# RL6845_IP_SVD register map
Vendor: Realtek
Registers are 32-bit, read-write, reset 0x0 unless marked. A register's access mark holds for its fields unless they carry their own. Offsets are from the block's base; [hi:lo] are bit positions; {n}, {i} and the like mark numbered series.

## ipsec
Base 0x40100000
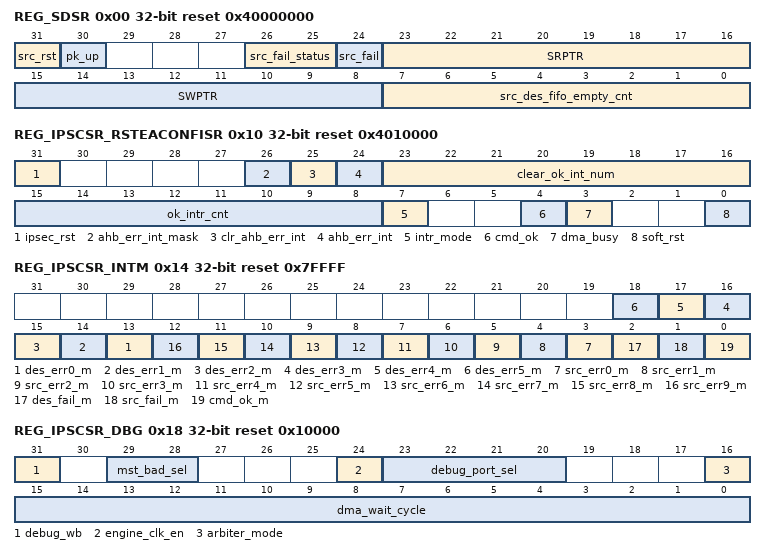
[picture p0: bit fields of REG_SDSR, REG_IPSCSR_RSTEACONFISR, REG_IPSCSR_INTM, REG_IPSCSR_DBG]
0x00 REG_SDSR access per field reset 0x40000000 — Source Descriptor Status Register
  [31] src_rst rw — Source descriptor reset. (only for pk_up = 1'b1)
  [30] pk_up rw — Packet base update wptr to engine. If pk_up =1, the total number of source descriptor in one packet can't be over 16, and the total number of destination descriptor in one packet can't be over 8.
  [26:25] src_fail_status ro — Source descriptor failed status. 2'd1: Users write the first word twice consecutively 2'd2: Users write the second word directly without writing first word in the beginning 2'd3: Overflow (Detect users try to write source descriptor, but there isn't available FIFO node to use).
  [24] src_fail rw — Source descriptor failed interrupt. Write 1 to clear this bit.
  [23:16] SRPTR ro — Source descriptor FIFO read pointer. When engine reads a descriptor and finishes it, SRPTR = SRPTR+2.
  [15:8] SWPTR ro — Source descriptor FIFO write pointer. When write descriptor to SDSW successfully, SWPTR = SWPTR+2.
  [7:0] src_des_fifo_empty_cnt ro — Source descriptor FIFO empty counter. Use this field to check how many available FIFO nodes in source descriptor FIFO could use.
0x04 REG_SDFWR — Source Descriptor First Word Register
  [31:0] SDFW — Source Descriptor First Word
0x08 REG_SDSWR — Source Descriptor Second Word Register
  [31:0] SDSW — Source Descriptor Second Word
0x10 REG_IPSCSR_RSTEACONFISR access per field reset 0x4010000 — Reset Engine and Configure Interrupt Service Routine Register
  [31] ipsec_rst rw — IPsec engine reset. Write '1' to reset the crypto engine and DMA engine (used to clear fatal error).
  [26] ahb_err_int_mask rw
  [25] clr_ahb_err_int rw
  [24] ahb_err_int ro
  [23:16] clear_ok_int_num rw — Clear ok interrupt number. In interrupt counter mode, if the programmer wants to clear ok_intr_cnt, need to write ok_intr_cnt to this field first, then write '1' to cmd_ok.
  [15:8] ok_intr_cnt ro — Ok interrupt counter. Reading this field can know how many interrupts are coming to notify that crypto engine has calculated cryptographic feature results. Use this field in interrupt counter mode.
  [7] intr_mode rw — Select ok interrupt mode: 1'd0: Interrupt mode is general mode. 1'd1: Interrupt mode is counter mode. · General mode means no matter how many interrupts are coming to notify that crypto engine has calculated cryptographic feature results. There is always one interrupt signal shows in cmd_ok field, and nothing in ok_intr_cnt. So if the programmer want to clear this signal, just write '1' to cmd_ok. · Counter mode means the programmer can know how many interrupts are coming to notify that crypto engine has calculated cryptographic feature results from ok_intr_cnt. The programmer also can know there are at least one interrupt from reading cmd_ok. So if the programmer want to clear ok_intr_cnt signals, need to write ok_intr_cnt into clear_ok_int_num, then write '1' to cmd_ok.
  [4] cmd_ok rw — Command ok Interrupt. Reading this field to detect whether crypto engine has calculated a cryptographic feature result. Even if interrupt mode is counter mode, still can use this field to detect whether an interrupt is coming. Write '1' to clear this interrupt signal.
  [3] dma_busy ro — Detect whether IPsec DMA is busy: 1'd0: DMA is not busy 1'd1: DMA is busy Used for debug to avoid data coherence issue (when user gets crypto finish calculated interrupt, user can make sure DMA engine has already move data to result buffer.)
  [0] soft_rst wo — Software reset. Write '1' to reset the crypto engine.
0x14 REG_IPSCSR_INTM reset 0x7FFFF — Interrupt Mask Register
  [n+13] des_err{n}_m (n=0..5) — Destination Descriptor Error {n} Interrupt Mask 1'd0: Disable mask 1'd1: Enable mask
  [n+3] src_err{n}_m (n=0..9) — Source Descriptor Error {n} Interrupt Mask 1'd0: Disable mask 1'd1: Enable mask
  [2] des_fail_m — Source Descriptor fail interrupt mask. 1'd0: Disable mask 1'd1: Enable mask
  [1] src_fail_m — Destination Descriptor fail interrupt mask. 1'd0: Disable mask 1'd1: Enable mask
  [0] cmd_ok_m — Command ok Interrupt Mask. 1'd0: Disable mask 1'd1: Enable mask If the programmer wants to disable cmd_ok interrupt signal, write '1' to enable interrupt mask.
0x18 REG_IPSCSR_DBG reset 0x10000 — Debug Register
  [31] debug_wb — Debug: write back mode. 1'd0: Disable DMA write back mode. 1'd1: Enable DMA write back mode. Enable this field, crypto DMA will move data from source address to destination address. During this period, the data won't be processed in any calculation (encryption, decryption, hash), then the programmer can check whether the source data is the same as destination data.
  [29:28] mst_bad_sel — (For debug port) select Lexra master data bus (option) 2'd0: mst_ipsec_bad[07:00] 2'd1: mst_ipsec_bad[15:08] 2'd2: mst_ipsec_bad[23:16] 2'd3: mst_ipsec_bad[31:24]
  [24] engine_clk_en — IPsec engine clock enable 1'd0: Disable IPsec engine clock 1'd1: Enable IPsec engine clock
  [23:20] debug_port_sel — Debug port selection 4'd0: engine_debug 4'd1: dma_lexra_debug 4'd2: dma_rx_debug 4'd3: dma_tx_debug
  [16] arbiter_mode — DMA arbiter mode: 1'd0: round-robin 1'd1: detect fifo wasted level There are 2 FIFOs in DMA, that are read-FIFO and write-FIFO. Detecting FIFO wasted level means that DMA will process which FIFO first depends on which wasted level is high. Because the wasted level is high means there are many FIFO nodes waiting to be processed in this FIFO, so DMA must process them in hurry.
  [15:0] dma_wait_cycle — Setting DMA wait cycles to assert next DMA request
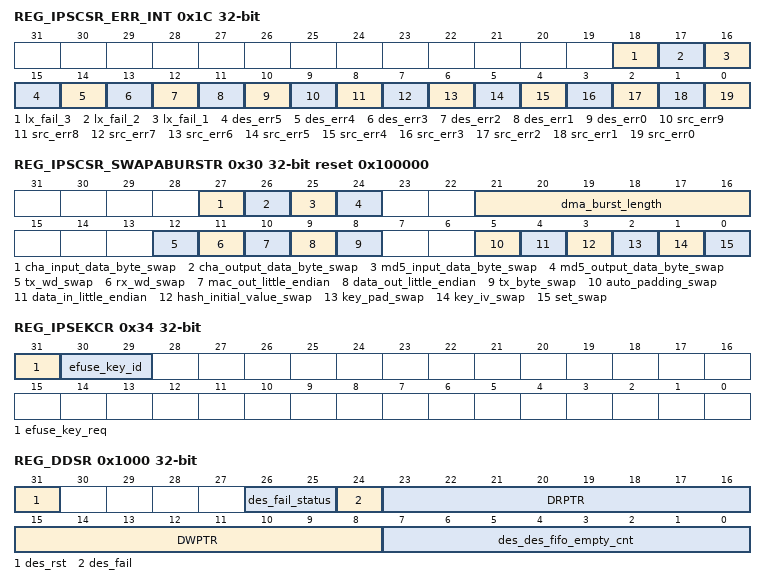
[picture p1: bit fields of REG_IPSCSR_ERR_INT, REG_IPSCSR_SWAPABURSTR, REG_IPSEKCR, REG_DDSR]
0x1C REG_IPSCSR_ERR_INT ro — Error Interrupt Register
  [18] lx_fail_3 — When a burst done, burst length != burst cnt. Write "1" to clear this error signal.
  [17] lx_fail_2 — When IPsec is working, rdata from bus != rdata of ipsec or wdata of ipsec != wdata on bus Write "1" to clear this error signal.
  [16] lx_fail_1 — LX bus timing issue Write "1" to clear this error signal.
  [15] des_err5 — Destination Descriptor Error 5 Interrupt. The error condition is authentication digest length error in destination descriptor. MD5: adl != 16 or SHA1: adl != 20 or SHA2-224: adl != 28 or adl != 32 when set sequential hash and not sequential hash last SHA2-256: adl != 32 or SHA2-384: adl != 48 or adl != 64 when set sequential hash and not sequential hash last SHA2-512: adl != 64 Write '1' to clear this error signal.
  [14] des_err4 — Destination Descriptor Error 4 Interrupt. The error condition is authentication digest length error in destination descriptor. MD5: adl > 16 or SHA1: adl > 20 or SHA2-224: adl > 28 or adl > 32when set sequential hash and not sequential hash last SHA2-256: adl > 32 or SHA2-384: adl > 48 or adl > 64when set sequential hash and not sequential hash last SHA2-512: adl > 64 Write '1' to clear this error signal.
  [13] des_err3 — Destination Descriptor Error 3 Interrupt. One of the error condition is that the sum of enl is greater than Encryption Total Length. The other error condition is about destination descriptor length error ((enl(Encryption length)==0) & (adl(authentication data length)==0)). Write '1' to clear this error signal. Sum of enl reference the register REG_IPSCSR_SENLR (offset 0x24).
  [12] des_err2 — Destination Descriptor Error 2 Interrupt. The error condition is the bit field ENC=1'b0 (active Hash engine to process hash data), but only active cipher engine. Write '1' to clear this error signal.
  [11] des_err1 — Destination Descriptor Error 1 Interrupt. The error condition is the bit field ENC=1'b1 (active cipher engine to process cipher data), but only active hash engine. Write '1' to clear this error signal.
  [10] des_err0 — Destination Descriptor Error 0 Interrupt. One of the error condition is destination descriptor starting address error (DDSA[1:0]!=2'd0 [At least 4 bytes-aligned]). The other error condition is memory protection event. Write '1' to clear this error signal.
  [9] src_err9 — Source Descriptor Error 9 Interrupt. The error condition is that sum of epl is not equal to EPTL (Encryption Padding Total Length). Write '1' to clear this error signal. Sum of epl reference the register REG_IPSCSR_SEPLR (offset 0x2C).
  [8] src_err8 — Source Descriptor Error 8 Interrupt. The error condition is that sum of apl is not equal to HPTL (Hash Padding Total Length). Write '1' to clear this error signal. Sum of apl reference the register REG_IPSCSR_SAPLR (offset 0x28).
  [7] src_err7 — Source Descriptor Error 7 Interrupt. The error condition is that sum of enl is not equal to ETL (Encryption Total Length). Write '1' to clear this error signal. Sum of enl reference the register REG_IPSCSR_SENLR (offset 0x24).
  [6] src_err6 — Source Descriptor Error 6 Interrupt. The error condition is that sum of a2eo is not equal to HTL (Header Total Length). Write '1' to clear this error signal. Sum of a2eo reference the register REG_IPSCSR_SAADLR (offset 0x20).
  [5] src_err5 — Source Descriptor Error 5 Interrupt. The error condition is that there is a source descriptor, but the data length ((a2eo/epl) +(enl) + (apl)) is 0. Write '1' to clear this error signal.
  [4] src_err4 — Source Descriptor Error 4 Interrupt. The error condition is source data buffer pointer error (SDBP[1:0]!=2'd0 [At least 4 byte aligned]). Write '1' to clear this error signal.
  [3] src_err3 — Source Descriptor Error 3 Interrupt. About source descriptor length error. One of the error condition is setting the first descriptor but (CL!=3). The other error condition is that there is a source descriptor but CL, KL, IL, PL, SHIVL are all 0. Write '1' to clear this error signal.
  [2] src_err2 — Source Descriptor Error 2 Interrupt. One of the error condition is source descriptor starting address error (SDSA[1:0]!=2'd0 [At least 4 bytes-aligned]). The other error condition is memory protection event. Write '1' to clear this error signal.
  [1] src_err1 — Source Descriptor Error 1 Interrupt. The error condition is last segment descriptor is set (LS=1), when descriptor is pointing to the first segment of the packet. Write '1' to clear this error signal.
  [0] src_err0 — Source Descriptor Error 0 Interrupt. One of the error condition is that first segment descriptor is not set (FS=0), when descriptor is pointing to the first segment of the packet. The other error condition is that first segment descriptor is set (FS=1), when descriptor is not pointing to the first segment of the packet. Write '1' to clear this error signal.
0x20 REG_IPSCSR_SADDLR ro — Sum of Additional Authentication Data Length Register
  [10:0] a2eo_sum — Sum of additional authentication data length.
0x24 REG_IPSCSR_SENLR ro — Sum of Encryption Data Length Register
  [23:0] enl_sum — Sum of encryption data length.
0x28 REG_IPSCSR_SAPLR ro — Sum of Authentication Padding Data Length Register
  [11:0] apl_sum — Sum of authentication padding data length.[Mix mode uses this field]
0x2C REG_IPSCSR_SEPLR ro — Sum of Encryption Padding Data Length Register
  [5:0] epl_sum — Sum of encryption padding data length. [Mix mode uses this field]
0x30 REG_IPSCSR_SWAPABURSTR reset 0x100000 — Swap and Burst Register
  [27] cha_input_data_byte_swap — Byte swap for CHA input data 1: Enable 0: Disable
  [26] cha_output_data_byte_swap — Byte swap for CHA output data 1: Enable 0: Disable
  [25] md5_input_data_byte_swap — Byte swap for MD5 input data 1: Enable 0: Disable
  [24] md5_output_data_byte_swap — Byte swap for MD5 output data 1: Enable 0: Disable
  [21:16] dma_burst_length — Set DMA burst length. The maximum setting length is 16 bursts. The minimum setting length is 1 burst. Note: If all bits are zero (6'd0), it means that the maximum burst size or undefined burst size.
  [12] tx_wd_swap — Word swap for dma_tx engine input data: 1'd0: Disable 1'd1: Enable
  [11] rx_wd_swap — Word swap for dma_rx engine output data: 1'd0: Disable 1'd1: Enable
  [10] mac_out_little_endian — Output mac is little endian: 1'd0: Big endian 1'd1: Little endian
  [9] data_out_little_endian — Output data is little endian: 1'd0: Big endian 1'd1: Little endian
  [8] tx_byte_swap — Byte swap for dma_tx engine input data: 1'd0: Disable 1'd1: Enable
  [5] auto_padding_swap — Byte swap for padding_len input data 1: Enable 0: Disable
  [4] data_in_little_endian — Input data is little endian: 1'd0: Big endian 1'd1: Little endian
  [3] hash_initial_value_swap — Byte swap for sequential hash initial value: 1'd0: Disable 1'd1: Enable
  [2] key_pad_swap — Byte swap for HMAC key pad: 1'd0: Disable 1'd1: Enable
  [1] key_iv_swap — Byte swap for Cipher key and Initial Vector: 1'd0: Disable 1'd1: Enable
  [0] set_swap — Byte swap for command setting data: 1'd0: Disable 1'd1: Enable
0x34 REG_IPSEKCR — Key Control Register
  [31] efuse_key_req — Request of loading key from OTP, cleared by key_rdy
  [30:29] efuse_key_id — 2'b00: load key from OTP key1 2'b01: load key from OTP key2 2'b10: load key from OTP RSIP key_ecb 2'b11: load key from OTP RSIP key_ctr
0x40 REG_ENG_DBG ro — Crypto Engine Debug Register
  [31:0] eng_dbg — Crypto engine debug info
0x44 REG_DMA_LX_DBG ro — Crypto Engine DMA LX Bus Debug Register
  [31:0] dma_lx_dbg — Crypto engine LX bus debug info
0x48 REG_DMA_RX_DBG ro — Crypto Engine DMA Rx Debug Register
  [31:0] dma_rx_dbg — Crypto engine DMA Rx debug info
0x4C REG_DMA_TX_DBG ro — Crypto Engine DMA Tx Debug Register
  [31:0] dma_tx_dbg — Crypto engine DMA Tx debug info
0x1000 REG_DDSR access per field — Destination Descriptor Status Register
  [31] des_rst rw — Destination descriptor reset. (only for pk_up = 1'b1)
  [26:25] des_fail_status ro — Destination Descriptor failed status: 2'd1: Users write the first word twice consecutively 2'd2: Users write the second word directly without writing first word in the beginning 2'd3: Overflow (detect users try to write source descriptor, but there isn't available FIFO node to use).
  [24] des_fail rw — Destination descriptor failed interrupt. Write 1 to clear this bit.
  [23:16] DRPTR ro — Destination descriptor FIFO read pointer. When engine reads a descriptor and finished it, DRPTR = DRPTR+2.
  [15:8] DWPTR ro — Destination descriptor FIFO write pointer. When writting descriptor to DDSW successfully, DWPTR = DWPTR+2.
  [7:0] des_des_fifo_empty_cnt ro — Destination descriptor FIFO empty counter. Use this field to check how many available FIFO nodes in Destination descriptor FIFO could use.
0x1004 REG_DDFWR — Destination Descriptor First Word Register
  [31:0] DDFW — Destination Descriptor First Word
0x1008 REG_DDSWR — Destination Descriptor Second Word Register
  [31:0] DDSW — Destination Descriptor Second Word
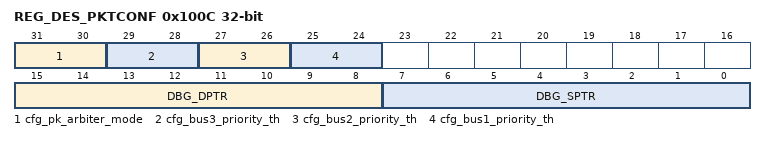
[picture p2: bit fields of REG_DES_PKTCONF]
0x100C REG_DES_PKTCONF — Packet Configure Register
  [31:30] cfg_pk_arbiter_mode — Arbiter rule between secure and no-secure access 0: round-robin 1/2/3: decided by the load_count of source descpritor FIFO of secure and no-secure, the more full is the winner.
  [29:28] cfg_bus3_priority_th — The priority of bus3 (reserved now)
  [27:26] cfg_bus2_priority_th — The priority of bus2-- security access. If 0x100C[31:30]=1, the load_count of source descriptor FIFO is wr_ptr - rd_ptr + 0x100C[27:26]. Otherwise, the load_count of source descriptor FIFO is wr_ptr - rd_ptr.
  [25:24] cfg_bus1_priority_th — The priority of bus2-- non-secure access. If 0x100C[31:30]=1, the load_count of source descriptor FIFO is wr_ptr - rd_ptr + 0x100C[25:24]. Otherwise, the load_count of source descriptor FIFO is wr_ptr - rd_ptr.
  [15:8] DBG_DPTR — Destination descriptor FIFO read pointer: Users read this pointer value can know what the ID number of FIFO node that is now pointed by read pointer is. If users want to know what the 32 bits value of a specified FIFO node, users can write an ID number to this read pointer, then get the 32 bits value from Debug Destination Descriptor Data Register.
  [7:0] DBG_SPTR — Source descriptor FIFO read pointer: Users read this pointer value can know what the ID number of FIFO node that is now pointed by read pointer is. If users want to know what the 32 bits value of a specified FIFO node, users can write an ID number to this read pointer, then get the 32 bits value from Debug Source Descriptor Data Register.
0x1010 REG_DBGSDR ro — Debug Source Descriptor Data Register
  [31:0] DBG_SD — Debug Source Descriptor Data: This register is used with DBG_SPTR.
0x1014 REG_DBGDDR ro — Debug Destination Descriptor Data Register
  [31:0] DBG_DD — Debug Destination Descriptor Data: This register is used with DBG_DPTR.
0x1018 REG_DUMMY — Dummy Register
  [31:0] dummy — HW used only (reserved)
